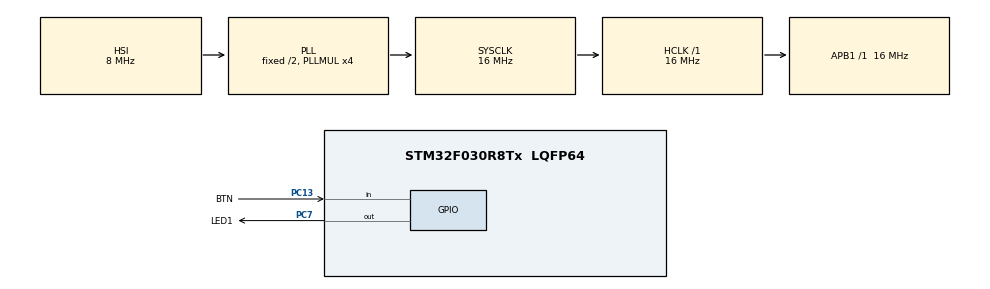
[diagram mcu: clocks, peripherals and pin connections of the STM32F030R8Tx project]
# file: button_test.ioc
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Mcu.Family=STM32F0
Mcu.Name=STM32F030R8Tx
Mcu.Package=LQFP64
NVIC.TIM3_IRQn=true\:0\:0\:false\:false\:true\:true\:true\:true
PC13.GPIO_Label=BTN
PC13.Signal=GPIO_Input
PC7.GPIO_Label=LED1
PC7.PinState=GPIO_PIN_SET
PC7.Signal=GPIO_Output
ProjectManager.HeapSize=0x200
ProjectManager.StackSize=0x400
ProjectManager.TargetToolchain=STM32CubeIDE
RCC.AHBFreq_Value=16000000
RCC.APB1Freq_Value=16000000
RCC.APB1TimFreq_Value=16000000
RCC.HCLKFreq_Value=16000000
RCC.PLLMUL=RCC_PLL_MUL4
RCC.SYSCLKFreq_VALUE=16000000
RCC.SYSCLKSource=RCC_SYSCLKSOURCE_PLLCLK
TIM3.Period=2000
TIM3.Prescaler=15999
VP_TIM3_VS_ClockSourceINT.Mode=Internal
board=custom

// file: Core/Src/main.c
/* USER CODE BEGIN Header */
/**
  ******************************************************************************
  * @file           : main.c
  * @brief          : Main program body
  ******************************************************************************
  * @attention
  *
  * Copyright (c) 2023 STMicroelectronics.
  * All rights reserved.
  *
  * This software is licensed under terms that can be found in the LICENSE file
  * in the root directory of this software component.
  * If no LICENSE file comes with this software, it is provided AS-IS.
  *
  ******************************************************************************
  */
/* USER CODE END Header */
#include "main.h"

TIM_HandleTypeDef htim3;

/* USER CODE BEGIN PV */
int kol = 0;
/* USER CODE END PV */

void SystemClock_Config(void);
static void MX_GPIO_Init(void);
static void MX_TIM3_Init(void);

int main(void)
{

  /* MCU Configuration--------------------------------------------------------*/

  /* Reset of all peripherals, Initializes the Flash interface and the Systick. */
  HAL_Init();

  /* Configure the system clock */
  SystemClock_Config();

  /* Initialize all configured peripherals */
  MX_GPIO_Init();
  MX_TIM3_Init();
  /* USER CODE BEGIN 2 */
  HAL_TIM_Base_Start_IT(&htim3); // включаем прерывание

  /* USER CODE END 2 */

  /* Infinite loop */
  /* USER CODE BEGIN WHILE */
  while (1)
  {

	  if (!HAL_GPIO_ReadPin(BTN_GPIO_Port, BTN_Pin)){
		  if(kol == 0)
		  {
			  HAL_TIM_Base_Start(&htim3);
		  }
		  else
		  {
			  HAL_TIM_Base_Stop(&htim3);
		  }
	  }
	  else
	  {
		  HAL_TIM_Base_Stop(&htim3);
		  __HAL_TIM_SET_COUNTER(&htim3, 0x0000);
		  kol = 0;
	  }

    /* USER CODE END WHILE */

  }
}

void SystemClock_Config(void)
{
  RCC_OscInitTypeDef RCC_OscInitStruct = {0};
  RCC_ClkInitTypeDef RCC_ClkInitStruct = {0};

  /** Initializes the RCC Oscillators according to the specified parameters
  * in the RCC_OscInitTypeDef structure.
  */
  RCC_OscInitStruct.OscillatorType = RCC_OSCILLATORTYPE_HSI;
  RCC_OscInitStruct.HSIState = RCC_HSI_ON;
  RCC_OscInitStruct.HSICalibrationValue = RCC_HSICALIBRATION_DEFAULT;
  RCC_OscInitStruct.PLL.PLLState = RCC_PLL_ON;
  RCC_OscInitStruct.PLL.PLLSource = RCC_PLLSOURCE_HSI;
  RCC_OscInitStruct.PLL.PLLMUL = RCC_PLL_MUL4;
  RCC_OscInitStruct.PLL.PREDIV = RCC_PREDIV_DIV1;
  if (HAL_RCC_OscConfig(&RCC_OscInitStruct) != HAL_OK)
  {
    Error_Handler();
  }

  /** Initializes the CPU, AHB and APB buses clocks
  */
  RCC_ClkInitStruct.ClockType = RCC_CLOCKTYPE_HCLK|RCC_CLOCKTYPE_SYSCLK
                              |RCC_CLOCKTYPE_PCLK1;
  RCC_ClkInitStruct.SYSCLKSource = RCC_SYSCLKSOURCE_PLLCLK;
  RCC_ClkInitStruct.AHBCLKDivider = RCC_SYSCLK_DIV1;
  RCC_ClkInitStruct.APB1CLKDivider = RCC_HCLK_DIV1;

  if (HAL_RCC_ClockConfig(&RCC_ClkInitStruct, FLASH_LATENCY_0) != HAL_OK)
  {
    Error_Handler();
  }
}

static void MX_TIM3_Init(void)
{

  TIM_ClockConfigTypeDef sClockSourceConfig = {0};
  TIM_MasterConfigTypeDef sMasterConfig = {0};

  htim3.Instance = TIM3;
  htim3.Init.Prescaler = 15999;
  htim3.Init.CounterMode = TIM_COUNTERMODE_UP;
  htim3.Init.Period = 2000;
  htim3.Init.ClockDivision = TIM_CLOCKDIVISION_DIV1;
  htim3.Init.AutoReloadPreload = TIM_AUTORELOAD_PRELOAD_DISABLE;
  if (HAL_TIM_Base_Init(&htim3) != HAL_OK)
  {
    Error_Handler();
  }
  sClockSourceConfig.ClockSource = TIM_CLOCKSOURCE_INTERNAL;
  if (HAL_TIM_ConfigClockSource(&htim3, &sClockSourceConfig) != HAL_OK)
  {
    Error_Handler();
  }
  sMasterConfig.MasterOutputTrigger = TIM_TRGO_RESET;
  sMasterConfig.MasterSlaveMode = TIM_MASTERSLAVEMODE_DISABLE;
  if (HAL_TIMEx_MasterConfigSynchronization(&htim3, &sMasterConfig) != HAL_OK)
  {
    Error_Handler();
  }

}

static void MX_GPIO_Init(void)
{
  GPIO_InitTypeDef GPIO_InitStruct = {0};

  /* GPIO Ports Clock Enable */
  __HAL_RCC_GPIOC_CLK_ENABLE();

  /*Configure GPIO pin Output Level */
  HAL_GPIO_WritePin(LED1_GPIO_Port, LED1_Pin, GPIO_PIN_SET);

  /*Configure GPIO pin : BTN_Pin */
  GPIO_InitStruct.Pin = BTN_Pin;
  GPIO_InitStruct.Mode = GPIO_MODE_INPUT;
  GPIO_InitStruct.Pull = GPIO_NOPULL;
  HAL_GPIO_Init(BTN_GPIO_Port, &GPIO_InitStruct);

  /*Configure GPIO pin : LED1_Pin */
  GPIO_InitStruct.Pin = LED1_Pin;
  GPIO_InitStruct.Mode = GPIO_MODE_OUTPUT_PP;
  GPIO_InitStruct.Pull = GPIO_NOPULL;
  GPIO_InitStruct.Speed = GPIO_SPEED_FREQ_LOW;
  HAL_GPIO_Init(LED1_GPIO_Port, &GPIO_InitStruct);

}

/* USER CODE BEGIN 4 */
void HAL_TIM_PeriodElapsedCallback(TIM_HandleTypeDef *htim)
{
	  	if (htim->Instance == TIM3)
	  	{
	  		HAL_GPIO_TogglePin(LED1_GPIO_Port, LED1_Pin);
	  		kol = 1;
	  	}
}
/* USER CODE END 4 */

void Error_Handler(void)
{
  __disable_irq();
  while (1)
  {
  }
}
